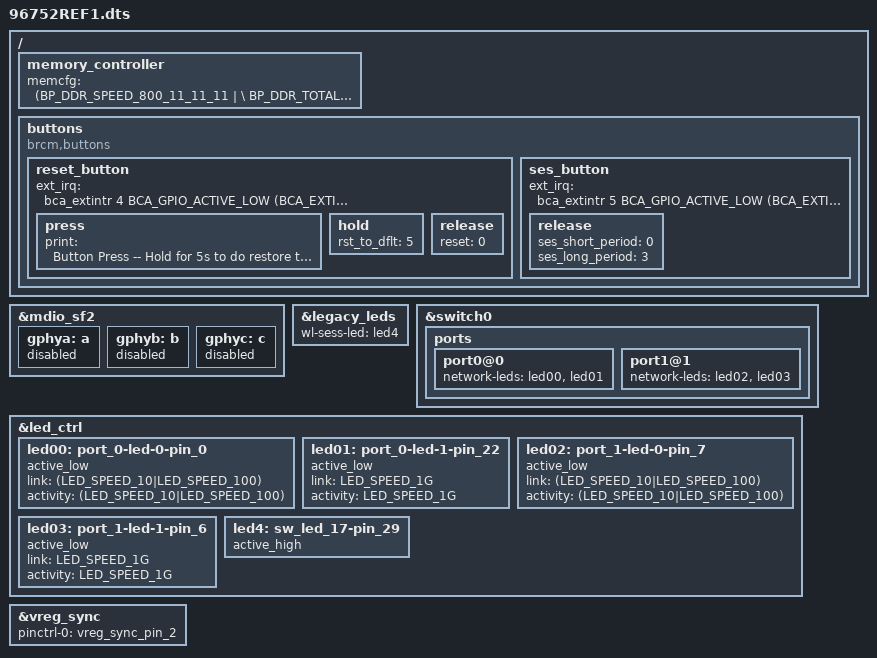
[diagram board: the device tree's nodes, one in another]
#include "63178.dtsi"

/ {
    memory_controller {
        memcfg = <(BP_DDR_SPEED_800_11_11_11 | \
                   BP_DDR_TOTAL_SIZE_512MB   | \
                   BP_DDR_DEVICE_WIDTH_16    | \
                   BP_DDR_TOTAL_WIDTH_16BIT  | \
                   BP_DDR_63178_DEFAULT)>;
    };

	buttons {
		compatible = "brcm,buttons";
		reset_button {
			ext_irq = <&bca_extintr 4 BCA_GPIO_ACTIVE_LOW (BCA_EXTINTR_TYPE_LOW_LEVEL | BCA_EXTINTR_TYPE_SENSE_EDGE)>;
			press {
				print = "Button Press -- Hold for 5s to do restore to default";
			};
			hold {
				rst_to_dflt = <5>;
			};
			release {
				reset = <0>;
			};	
		};
		ses_button {
			ext_irq = <&bca_extintr 5 BCA_GPIO_ACTIVE_LOW (BCA_EXTINTR_TYPE_LOW_LEVEL | BCA_EXTINTR_TYPE_SENSE_EDGE)>;
			release {
				ses_short_period = <0>;
				ses_long_period = <3>;
			};
		};
	};
};

&mdio_sf2 {
	/* Disable EGPHY2~EGPHY4 */
	gphya:a {
		status = "disabled";
	};
	gphyb:b {
		status = "disabled";
	};
	gphyc:c {
		status = "disabled";
	};
};

&legacy_leds {
	wl-sess-led = <&led4>;
};


&switch0 {
	ports {
		port0@0 {
			network-leds = <&led00 &led01>;
			status = "okay";
		};

		port1@1 {
			network-leds = <&led02 &led03>;
			status = "okay";
		};
	};
};

&led_ctrl {
	/* GPHY0_100/10M */
	led00: port_0-led-0-pin_0 {
		active_low;
		link = <(LED_SPEED_10|LED_SPEED_100)>;
		activity = <(LED_SPEED_10|LED_SPEED_100)>;
		status = "okay";
	};

	/* GPHY0_1G */
	led01: port_0-led-1-pin_22 {
		active_low;
		link = <LED_SPEED_1G>;
		activity = <LED_SPEED_1G>;
		status = "okay";
	};

	/* GPHY1_100/10M */
	led02: port_1-led-0-pin_7 {
		active_low;
		link = <(LED_SPEED_10|LED_SPEED_100)>;
		activity = <(LED_SPEED_10|LED_SPEED_100)>;
		status = "okay";
	};

	/* GPHY1_1G */
	led03: port_1-led-1-pin_6 {
		active_low;
		link = <LED_SPEED_1G>;
		activity = <LED_SPEED_1G>;
		status = "okay";
	};
	led4: sw_led_17-pin_29 {
		active_high;
		status = "okay";
	};
};

&vreg_sync {
		pinctrl-0 = <&vreg_sync_pin_2>;
		pinctrl-names = "default";
};

